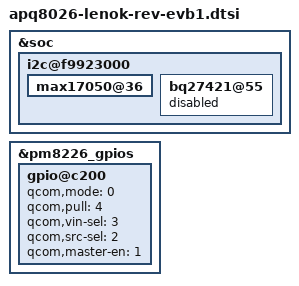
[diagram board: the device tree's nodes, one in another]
/* Copyright (c) 2014 LGE Inc.
 *
 * This program is free software; you can redistribute it and/or modify
 * it under the terms of the GNU General Public License version 2 and
 * only version 2 as published by the Free Software Foundation.
 *
 * This program is distributed in the hope that it will be useful,
 * but WITHOUT ANY WARRANTY; without even the implied warranty of
 * MERCHANTABILITY or FITNESS FOR A PARTICULAR PURPOSE.  See the
 * GNU General Public License for more details.
 */

#include "apq8026-lenok.dtsi"

&soc {
	i2c@f9923000 {
		max17050@36 {
			status = "okay";
		};
		bq27421@55 {
			status = "disabled";
		};
	};
};

&pm8226_gpios {
	gpio@c200 { /* GPIO 3 */     /* NFC_CLK_REQ */
		qcom,mode = <0>;         /* QPNP_PIN_MODE_DIG_IN */
		qcom,pull = <4>;         /* QPNP_PIN_PULL_DN - Not Fixed */
		qcom,vin-sel = <3>;      /* QPNP_PIN_VIN2 */
		qcom,src-sel = <2>;      /* QPNP_PIN_SEL_FUNC_1 */
		qcom,master-en = <1>;    /* Enable GPIO */
	};
};
